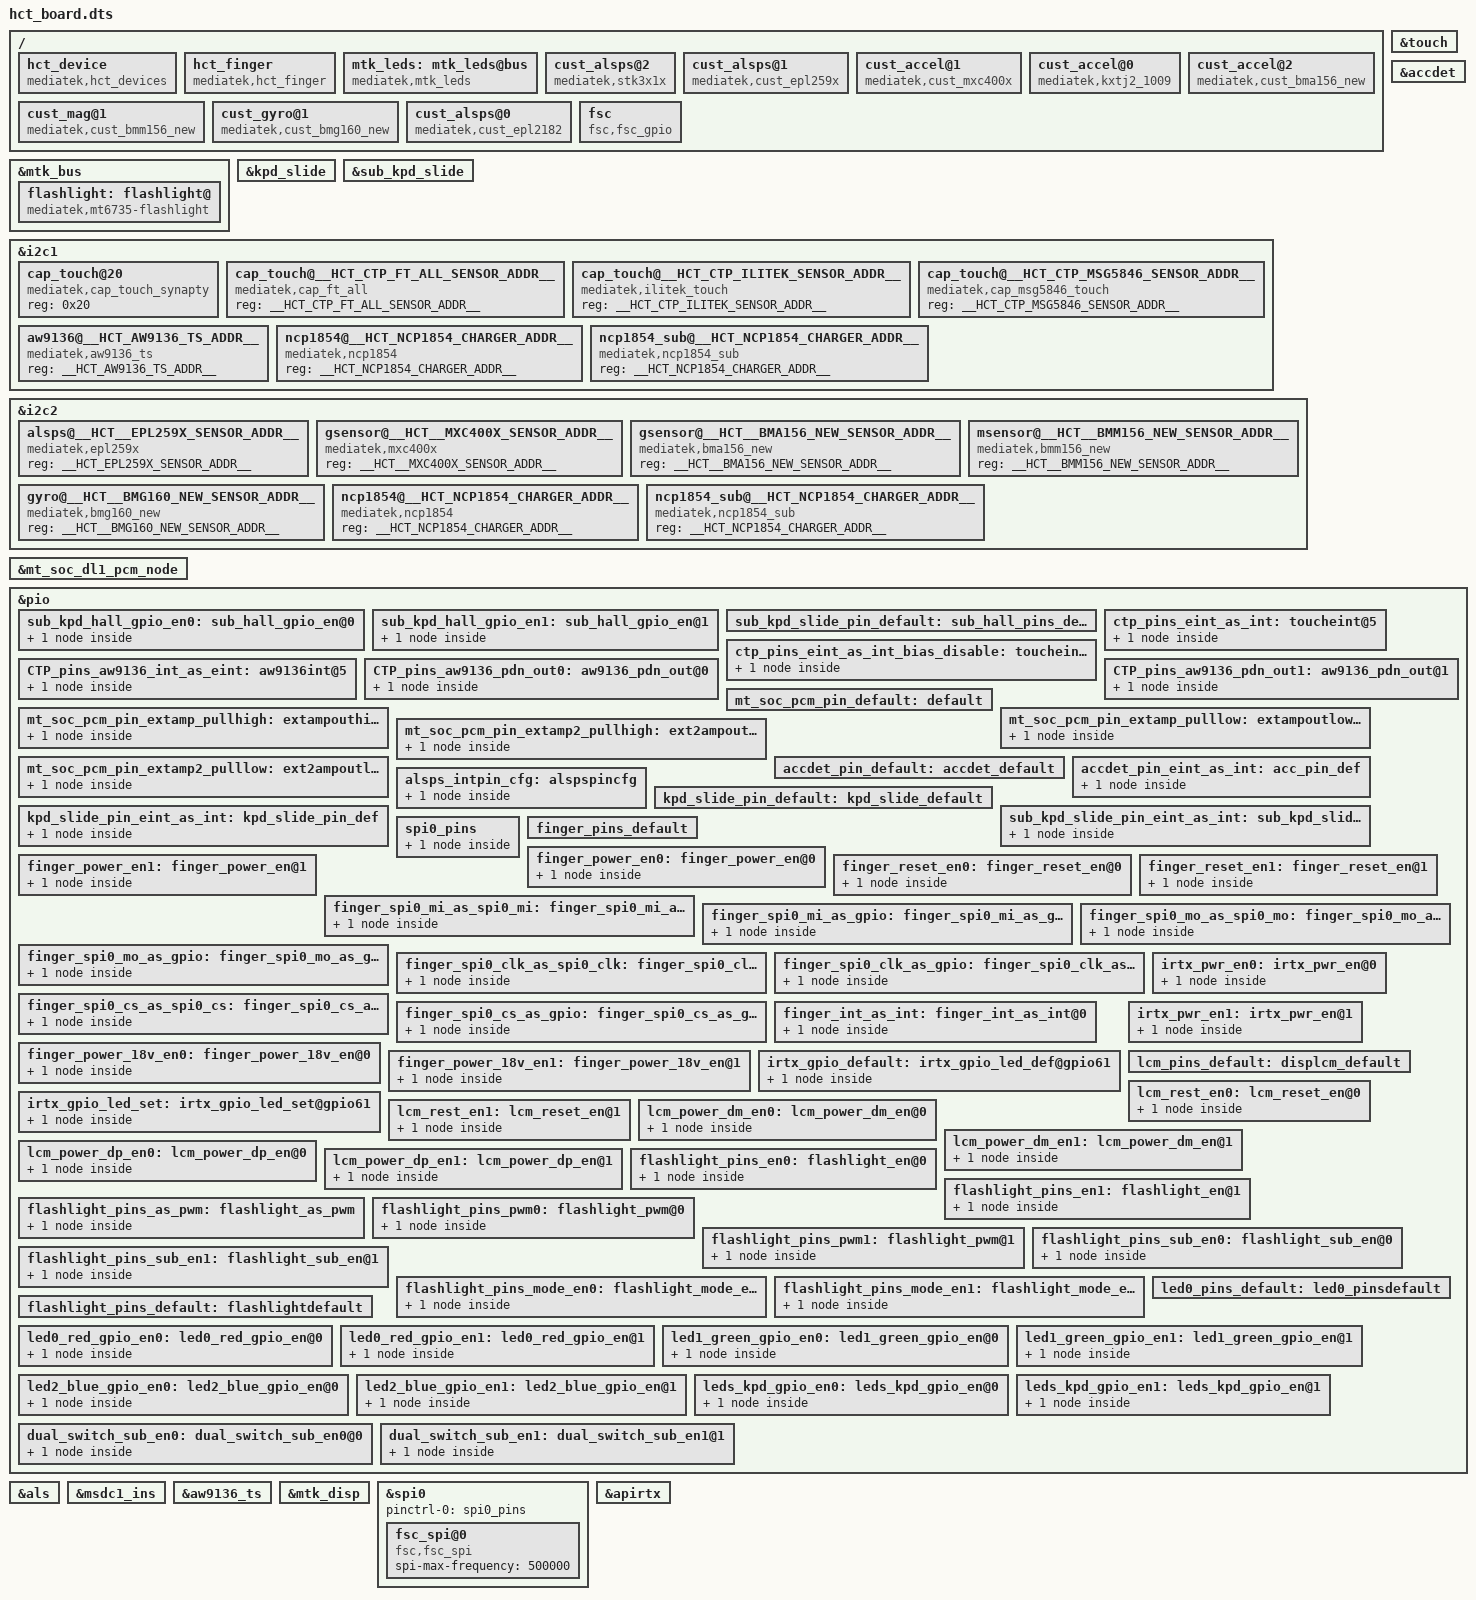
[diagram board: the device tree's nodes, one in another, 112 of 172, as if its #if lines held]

&touch {
      vtouch-supply = <&mt_pmic_vgp1_ldo_reg>;
};

&mtk_bus {



	flashlight: flashlight@ {
		compatible = "mediatek,mt6735-flashlight",
			     "mediatek,mt6735m-flashlight";
#if __HCT_FLASHLIGHT_SGM3785_SUPPORT__
		flashlight_pwmnum = <__HCT_FLASHLIGHT_PWM_NUM__>;
#endif
		status = "okay";
		};

		
};

#if __HCT_HALL_SUPPORT__
&kpd_slide {
	interrupt-parent = <&eintc>;
	interrupts = <__HCT_HALL_EINT_PIN_NUM__ IRQ_TYPE_LEVEL_LOW>;
	debounce = <__HCT_HALL_EINT_PIN_NUM__ 0>;
	hall_gpio = <&pio __HCT_HALL_EINT_GPIO_NUM__ 0>;
	status = "okay";
};

&kpd_slide {
	pinctrl-names = "default", "kpd_slide_as_int";
	pinctrl-0 = <&kpd_slide_pin_default>;
	pinctrl-1 = <&kpd_slide_pin_eint_as_int>;
	status = "okay";
};
#endif


#if __HCT_SUB_HALL_SUPPORT__
&sub_kpd_slide {
	interrupt-parent = <&eintc>;
	interrupts = <__HCT_SUB_HALL_EINT_PIN_NUM__ IRQ_TYPE_LEVEL_LOW>;
	debounce = <__HCT_SUB_HALL_EINT_PIN_NUM__ 0>;
	sub_hall_gpio = <&pio __HCT_SUB_HALL_EINT_GPIO_NUM__ 0>;
	status = "okay";
};

&sub_kpd_slide {
	pinctrl-names = "default", "sub_kpd_slide_as_int","sub_kpd_hall_gpio_en0","sub_kpd_hall_gpio_en1";
	pinctrl-0 = <&sub_kpd_slide_pin_default>;
	pinctrl-1 = <&sub_kpd_slide_pin_eint_as_int>;
	pinctrl-2 = <&sub_kpd_hall_gpio_en0>;
	pinctrl-3 = <&sub_kpd_hall_gpio_en1>;
	status = "okay";
};

#endif

&i2c1 {
	#address-cells = <1>;
	#size-cells = <0>;
	cap_touch@20 {
		compatible = "mediatek,cap_touch_synapty";
		reg = <0x20>;
		status = "okay";
	};
	cap_touch@__HCT_CTP_FT_ALL_SENSOR_ADDR__ {
		compatible = "mediatek,cap_ft_all";
		reg = <__HCT_CTP_FT_ALL_SENSOR_ADDR__>;
		status = "okay";
	};
#if defined(__HCT_CTP_ILITEK_SENSOR_ADDR__)
#if __HCT_CTP_ILITEK_SENSOR_ADDR__
	cap_touch@__HCT_CTP_ILITEK_SENSOR_ADDR__ {
		compatible = "mediatek,ilitek_touch";
		reg = <__HCT_CTP_ILITEK_SENSOR_ADDR__>;
		status = "okay";
	};
#endif
#endif

#if defined(__HCT_CTP_MSG5846_SENSOR_ADDR__)
#if __HCT_CTP_MSG5846_SENSOR_ADDR__
	cap_touch@__HCT_CTP_MSG5846_SENSOR_ADDR__ {
		compatible = "mediatek,cap_msg5846_touch";
		reg = <__HCT_CTP_MSG5846_SENSOR_ADDR__>;
		status = "okay";
	};
#endif
#endif

#if __HCT_AW9136_TS_SUPPORT__
#if __HCT_AW9136_TS_I2C_BUS_NUM__==1
        aw9136@__HCT_AW9136_TS_ADDR__{
		compatible = "mediatek,aw9136_ts";
		reg = <__HCT_AW9136_TS_ADDR__>;
		status = "okay";
	};
#endif
#endif

#if __HCT_SWITCH_CHARGER_I2C_BUS_NUM__==1
        ncp1854@__HCT_NCP1854_CHARGER_ADDR__{
		compatible = "mediatek,ncp1854",
		             "mediatek,ncp1851";
		reg = <__HCT_NCP1854_CHARGER_ADDR__>;
		status = "okay";
	};
#endif

#if __HCT_SUB_SWITCH_CHARGER_I2C_BUS_NUM__==1
        ncp1854_sub@__HCT_NCP1854_CHARGER_ADDR__{
		compatible = "mediatek,ncp1854_sub",
		             "mediatek,ncp1851_sub";
		reg = <__HCT_NCP1854_CHARGER_ADDR__>;
		status = "okay";
	};
#endif

};
&i2c2 {
	alsps@__HCT__EPL259X_SENSOR_ADDR__ {
		compatible = "mediatek,epl259x";
		reg = <__HCT_EPL259X_SENSOR_ADDR__>;
		status = "okay";
	};

	gsensor@__HCT__MXC400X_SENSOR_ADDR__ {
		compatible = "mediatek,mxc400x";
		reg = <__HCT__MXC400X_SENSOR_ADDR__>;
		status = "okay";
	};
#if __HCT_BMA156_BMM156_SUPPORT__
	gsensor@__HCT__BMA156_NEW_SENSOR_ADDR__ {
		compatible = "mediatek,bma156_new";
		reg = <__HCT__BMA156_NEW_SENSOR_ADDR__>;
		status = "okay";
	};
	msensor@__HCT__BMM156_NEW_SENSOR_ADDR__ {
		compatible = "mediatek,bmm156_new";
		reg = <__HCT__BMM156_NEW_SENSOR_ADDR__>;
		status = "okay";
	};
	gyro@__HCT__BMG160_NEW_SENSOR_ADDR__ {
		compatible = "mediatek,bmg160_new";
		reg = <__HCT__BMG160_NEW_SENSOR_ADDR__>;
		status = "okay";
	};					
#endif
#if __HCT_SWITCH_CHARGER_I2C_BUS_NUM__==2
        ncp1854@__HCT_NCP1854_CHARGER_ADDR__{
		compatible = "mediatek,ncp1854",
		             "mediatek,ncp1851";
		reg = <__HCT_NCP1854_CHARGER_ADDR__>;
		status = "okay";
	};
#endif
#if __HCT_SUB_SWITCH_CHARGER_I2C_BUS_NUM__==2
        ncp1854_sub@__HCT_NCP1854_CHARGER_ADDR__{
		compatible = "mediatek,ncp1854_sub",
		             "mediatek,ncp1851_sub";
		reg = <__HCT_NCP1854_CHARGER_ADDR__>;
		status = "okay";
	};
#endif

};

&mt_soc_dl1_pcm_node {
	pinctrl-names = "default", "extamp-pullhigh", "extamp-pulllow","extamp2-pullhigh","extamp2-pulllow";
	pinctrl-0 = <&mt_soc_pcm_pin_default>;
	pinctrl-1 = <&mt_soc_pcm_pin_extamp_pullhigh>;
	pinctrl-2 = <&mt_soc_pcm_pin_extamp_pulllow>;
	pinctrl-3 = <&mt_soc_pcm_pin_extamp2_pullhigh>;
	pinctrl-4 = <&mt_soc_pcm_pin_extamp2_pulllow>;
	status = "okay";

};

&accdet{
	pinctrl-names = "default", "state_eint_as_int";
	pinctrl-0 = <&accdet_pin_default>;
	pinctrl-1 = <&accdet_pin_eint_as_int>;
	status = "okay";
};

&pio {

#if __HCT_SUB_HALL_SUPPORT__
/*hct sub_hall en setting*/
	sub_kpd_hall_gpio_en0: sub_hall_gpio_en@0 {
	    pins_cmd_dat {
			pins = <__HCT_SUB_HALL_GPIO_EN__>;
			slew-rate = <1>;
			output-low;
		};
	};
	sub_kpd_hall_gpio_en1: sub_hall_gpio_en@1 {
	    pins_cmd_dat {
			pins = <__HCT_SUB_HALL_GPIO_EN__>;
			slew-rate = <1>;
			output-high;
		};
	};
	sub_kpd_slide_pin_default: sub_hall_pins_default {
	};
#endif
	ctp_pins_eint_as_int: toucheint@5{
			pins_cmd_dat {
				pins = <__HCT_CTP_EINT_ENT_PINNUX__>;
				slew-rate = <0>;
				bias-pull-up = <00>;
			};
	};

	ctp_pins_eint_as_int_bias_disable: toucheint_bias_dis{
			pins_cmd_dat {
				pins = <__HCT_CTP_EINT_ENT_PINNUX__>;
				slew-rate = <0>;
				bias-disable;
			};
	};

/* this pin defined is aw9136 start*/

	CTP_pins_aw9136_int_as_eint: aw9136int@5{
#if __HCT_AW9136_INT_PINNUX__
			pins_cmd_dat {
				pins = <__HCT_AW9136_INT_PINNUX__>;
				slew-rate = <0>;
				bias-pull-up = <00>;
			};
#endif
	};

	CTP_pins_aw9136_pdn_out0: aw9136_pdn_out@0 {
#if __HCT_GPIO_AW9136_PDN_PINMUX__
	    pins_cmd_dat {
			pins = <__HCT_GPIO_AW9136_PDN_PINMUX__>;
			slew-rate = <1>;
			output-low;
		};
#endif
	};

	CTP_pins_aw9136_pdn_out1: aw9136_pdn_out@1 {
#if __HCT_GPIO_AW9136_PDN_PINMUX__
	    pins_cmd_dat {
			pins = <__HCT_GPIO_AW9136_PDN_PINMUX__>;
			slew-rate = <1>;
			output-high;
		};
#endif
	};

/* this pin defined is aw9136 end*/
	mt_soc_pcm_pin_default: default {

	};

	mt_soc_pcm_pin_extamp_pullhigh: extampouthigh@0 {
	    pins_cmd_dat {
			pins = <__HCT_GPIO_EXTAMP_EN_PIN__>;
			slew-rate = <1>; /*direction 0:in, 1:out*/
			output-high;/*direction out used only. output_low or high*/
		};
	};

	mt_soc_pcm_pin_extamp_pulllow: extampoutlow@1 {
	    pins_cmd_dat {
			pins = <__HCT_GPIO_EXTAMP_EN_PIN__>;/*GPIO_CAMERA_CMRST_PIN*/
			slew-rate = <1>;
			output-low;
		};
	};

	mt_soc_pcm_pin_extamp2_pullhigh: ext2ampouthigh@3 {
#if __HCT_GPIO_EXTAMP2_EN_PIN__
	    pins_cmd_dat {
			pins = <__HCT_GPIO_EXTAMP2_EN_PIN__>;/*GPIO_CAMERA_CMRST_PIN*/
			slew-rate = <1>; /*direction 0:in, 1:out*/
			output-high;/*direction out used only. output_low or high*/
		};
#endif
	};

	mt_soc_pcm_pin_extamp2_pulllow: ext2ampoutlow@4 {
#if __HCT_GPIO_EXTAMP2_EN_PIN__
	    pins_cmd_dat {
			pins = <__HCT_GPIO_EXTAMP2_EN_PIN__>;/*GPIO_CAMERA_CMRST_PIN*/
			slew-rate = <1>;
			output-low;
		};
#endif
	};

/*Accdet*/
	accdet_pin_default:accdet_default{
	};
	accdet_pin_eint_as_int:acc_pin_def{
	    pins_cmd_dat {
			pins = <__HCT_ACCDET_EINT_PIN__>;/*HCT_ACCDET_EINT_PIN*/
			slew-rate = <0>;/*direction 0:in, 1:out*/
			bias-disable;
		};
	};
/*Alsps INT pin*/
	alsps_intpin_cfg: alspspincfg {

	    pins_cmd_dat {
			pins = <__HCT_ALSPS_EINT_PINMUX__>;
			slew-rate = <0>;
			bias-disable;
		};
	};
#if __HCT_HALL_SUPPORT__
/* Kpd_slide pin*/
	kpd_slide_pin_default:kpd_slide_default{
	};
	kpd_slide_pin_eint_as_int:kpd_slide_pin_def{
	    pins_cmd_dat {
			pins = <__HCT_KPD_SLIDE_EINT_PIN__>;/*HCT_ACCDET_EINT_PIN*/
			slew-rate = <0>;/*direction 0:in, 1:out*/
			bias-pull-up= <00> ;
		};
	};
#endif

#if __HCT_SUB_HALL_SUPPORT__
/* sub_Kpd_slide pin*/
	sub_kpd_slide_pin_eint_as_int:sub_kpd_slide_pin_def{
	    pins_cmd_dat {
			pins = <__HCT_SUB_KPD_SLIDE_EINT_PIN__>;/*HCT_SUB_ACCDET_EINT_PIN*/
			slew-rate = <0>;/*direction 0:in, 1:out*/
			bias-pull-up= <00> ;
		};
	};
#endif

};

/*EInt setting node*/
&als {
	interrupt-parent = <&eintc>;
	interrupts = <__HCT_ALSPS_EINT_PIN_NUM__ IRQ_TYPE_LEVEL_LOW>;
	debounce = <__HCT_ALSPS_EINT_PIN_NUM__ 0>;
	status = "okay";
};

&accdet {
	interrupt-parent = <&eintc>;
	interrupts = <__HCT_ACCDET_EINT_PIN_NUM__ IRQ_TYPE_LEVEL_LOW>;
	debounce = <__HCT_ACCDET_EINT_PIN_NUM__ 256000>;
	status = "okay";
};

&touch {
	interrupt-parent = <&eintc>;
	interrupts = <__HCT_CTP_EINT_EN_PIN_NUM__ IRQ_TYPE_EDGE_FALLING>;
	debounce = <__HCT_CTP_EINT_EN_PIN_NUM__ 0>;
	status = "okay";
};

#if __HCT_SD_CARD_HOTPLUG_SUPPORT__
&msdc1_ins {
	interrupt-parent = <&eintc>;
	interrupts = <__HCT_MSDC_CD_EINT_NUM__ IRQ_TYPE_LEVEL_LOW>;
	debounce = <__HCT_MSDC_CD_EINT_NUM__ 512000>;
	status = "okay";
};
#endif

#if __HCT_AW9136_TS_SUPPORT__
&aw9136_ts {
	interrupt-parent = <&eintc>;
	interrupts = <__HCT_CTP_AW9136_INT_NUM__ IRQ_TYPE_LEVEL_LOW>;
	debounce = <__HCT_CTP_AW9136_INT_NUM__ 0>;
	status = "okay";
};
#endif


/ {

hct_device: hct_device{
	compatible				= "mediatek,hct_devices";
};
#if __HCT_FINGERPRINT_SUPPORT__
hct_finger: hct_finger{
	compatible				= "mediatek,hct_finger";
};
#endif

mtk_leds: mtk_leds@bus{
	compatible				= "mediatek,mtk_leds";
};
		cust_alsps@2 {
		compatible = "mediatek,stk3x1x";
		i2c_num	= <__HCT_ALSPS_I2C_BUS_NUM__>;
		i2c_addr = <__HCT_STK3X1X_SENSOR_ADDR__ 0 0 0>;
		polling_mode_ps = <0>;
		polling_mode_als = <1>;
		power_id = <0xffff>;
		power_vol = <0>;
		als_level = <5 9 36 59 82 132 205 273 500 845 1136 1545 2364 4655 6982>;
		als_value = <10 10 80 85 90 145 225 300 550 930 1250 1700 2600 5120 7680 10240>;
		ps_threshold_high		=  <__HCT_HCT_STK3X1X_PS_THRELD_HIGH__>;
		ps_threshold_low		=  <__HCT_HCT_STK3X1X_PS_THRELD_LOW__>;
		is_batch_supported_ps	= <0>;
		is_batch_supported_als	= <0>;
		};

		cust_alsps@1 {
		compatible				= "mediatek,cust_epl259x";
		i2c_num				= <__HCT_ALSPS_I2C_BUS_NUM__>;
		i2c_addr				= <__HCT_EPL259X_SENSOR_ADDR__ 0 0 0>;
		polling_mode_ps			= <0>;
		polling_mode_als		= <1>;
		power_id				= <0xffff>;
		power_vol				= <0>;
		als_level = <0 328 861 1377 3125 7721 7767 12621 23062 28430 33274 47116 57694 57694 65535>;
		als_value = <0 133 304 502 1004 2005 3058 5005 8008 10010 12000 16000 20000 20000 20000 20000>;
		ps_threshold_high		=  <__HCT_EPL259X_PS_THRELD_HIGH__>;
		ps_threshold_low		=  <__HCT_EPL259X_PS_THRELD_LOW__>;
		is_batch_supported_ps	= <0>;
		is_batch_supported_als	= <0>;
		};

		cust_accel@1 {
		compatible				= "mediatek,cust_mxc400x";
		i2c_num				= <__HCT_GSENSOR_I2C_BUS_NUM__>;
		i2c_addr				= <__HCT__MXC400X_SENSOR_ADDR__ 0 0 0>;
		direction				= <__HCT__MXC400X_SENSOR_DIRECTION__>;
		power_id				= <0xffff>;
		power_vol				= <0>;
		firlen					= <0>;
		is_batch_supported			= <__HCT__MXC400X_SENSOR_BATCH_SUPPORT__>;
		};

		cust_accel@0 {
		compatible				= "mediatek,kxtj2_1009";
		i2c_num				        = <__HCT_GSENSOR_I2C_BUS_NUM__>;
		i2c_addr				= <__HCT__KXTJ2_SENSOR_ADDR__ 0 0 0>;
		direction				= <__HCT__KXTJ2_SENSOR_DIRECTION__>;
		power_id				= <0xffff>;
		power_vol				= <0>;
		firlen					= <0>;
		is_batch_supported			= <__HCT__KXTJ2_SENSOR_BATCH_SUPPORT__>;
		};

#if __HCT_BMA156_BMM156_SUPPORT__		
		cust_accel@2 {
		compatible				= "mediatek,cust_bma156_new";
		i2c_num				    = <__HCT_GSENSOR_I2C_BUS_NUM__>;
		i2c_addr				= <__HCT__BMA156_NEW_SENSOR_ADDR__ 0 0 0>;
		direction				= <__HCT__BMA156_NEW_SENSOR_DIRECTION__>;
		power_id				= <0xffff>;
		power_vol				= <0>;
		firlen					= <0>;
		is_batch_supported		= <__HCT__BMA156_NEW_SENSOR_BATCH_SUPPORT__>;
		};
		
		cust_mag@1 {
		compatible				= "mediatek,cust_bmm156_new";
		i2c_num					= <__HCT_MSENSOR_I2C_BUS_NUM__>;
		i2c_addr				= <__HCT__BMM156_NEW_SENSOR_ADDR__ 0 0 0>;
		direction				= <__HCT__BMM156_NEW_SENSOR_DIRECTION__>;
		power_id				= <0xffff>;
		power_vol				= <0>;
		is_batch_supported		= <__HCT__BMM156_NEW_SENSOR_BATCH_SUPPORT__>;
		};

		cust_gyro@1 {
		compatible                      = "mediatek,cust_bmg160_new";
		i2c_num                         = <__HCT_GYRO_I2C_BUS_NUM__>;
		/* i2c_addr                     = <__HCT__BMG160_NEW_SENSOR_ADDR__ 0 0 0>; */
		direction                       = <__HCT__BMG160_NEW_SENSOR_DIRECTION__>;
		power_id                        = <0xffff>;
		power_vol                       = <0>;
		firlen                          = <0>;
		is_batch_supported              = <0>;
		};

#endif
		cust_alsps@0 {
		compatible				= "mediatek,cust_epl2182";
		i2c_num				= <__HCT_ALSPS_I2C_BUS_NUM__>;
		i2c_addr				= <__HCT_EPL2182_SENSOR_ADDR__ 0 0 0>;
		polling_mode_ps			= <0>;
		polling_mode_als		= <1>;
		power_id				= <0xffff>;
		power_vol				= <0>;
		als_level = <0 328 861 1377 3125 7721 7767 12621 23062 28430 33274 47116 57694 57694 65535>;
		als_value = <0 133 304 502 1004 2005 3058 5005 8008 10010 12000 16000 20000 20000 20000 20000>;
		ps_threshold_high		=  <__HCT_EPL2182_PS_THRELD_HIGH__>;
		ps_threshold_low		=  <__HCT_EPL2182_PS_THRELD_LOW__>;
		is_batch_supported_ps	= <0>;
		is_batch_supported_als	= <0>;
		};

};

&mtk_leds {
	pinctrl-names = "default", "led0_red_gpio_en0", "led0_red_gpio_en1","led1_green_gpio_en0", "led1_green_gpio_en1" ,"led2_blue_gpio_en0", 
                          "led2_blue_gpio_en1","leds_kpd_gpio_en0","leds_kpd_gpio_en1";
	pinctrl-0 = <&led0_pins_default>;
	pinctrl-1 = <&led0_red_gpio_en0>;
	pinctrl-2 = <&led0_red_gpio_en1>;
	pinctrl-3 = <&led1_green_gpio_en0>;
	pinctrl-4 = <&led1_green_gpio_en1>;
	pinctrl-5 = <&led2_blue_gpio_en0>;
	pinctrl-6 = <&led2_blue_gpio_en1>;
	pinctrl-7 = <&leds_kpd_gpio_en0>;
	pinctrl-8 = <&leds_kpd_gpio_en1>;
};


&mtk_disp {
	pinctrl-names = "default", "lcm_rest_en0", "lcm_rest_en1","lcm_power_dm_en0","lcm_power_dm_en1","lcm_power_dp_en0","lcm_power_dp_en1";
	pinctrl-0 = <&lcm_pins_default>;
	pinctrl-1 = <&lcm_rest_en0>;
	pinctrl-2 = <&lcm_rest_en1>;
	pinctrl-3 = <&lcm_power_dm_en0>;
	pinctrl-4 = <&lcm_power_dm_en1>;
	pinctrl-5 = <&lcm_power_dp_en0>;
	pinctrl-6 = <&lcm_power_dp_en1>;
};

#if __HCT_FINGERPRINT_SUPPORT__
&hct_finger{
	pinctrl-names = "default", "finger_power_en0","finger_power_en1","finger_reset_en0","finger_reset_en1","finger_spi0_mi_as_spi0_mi","finger_spi0_mi_as_gpio",
                          "finger_spi0_mo_as_spi0_mo","finger_spi0_mo_as_gpio","finger_spi0_clk_as_spi0_clk","finger_spi0_clk_as_gpio","finger_spi0_cs_as_spi0_cs",
                          "finger_spi0_cs_as_gpio","finger_int_as_int","finger_power_18v_en0","finger_power_18v_en1";
	pinctrl-0 = <&finger_pins_default>;
	pinctrl-1 = <&finger_power_en0>;
	pinctrl-2 = <&finger_power_en1>;
	pinctrl-3 = <&finger_reset_en0>;
	pinctrl-4 = <&finger_reset_en1>;
	pinctrl-5 = <&finger_spi0_mi_as_spi0_mi>;
	pinctrl-6 = <&finger_spi0_mi_as_gpio>;
	pinctrl-7 = <&finger_spi0_mo_as_spi0_mo>;
	pinctrl-8 = <&finger_spi0_mo_as_gpio>;
	pinctrl-9 = <&finger_spi0_clk_as_spi0_clk>;
	pinctrl-10= <&finger_spi0_clk_as_gpio>;
	pinctrl-11= <&finger_spi0_cs_as_spi0_cs>;
	pinctrl-12= <&finger_spi0_cs_as_gpio>;
	pinctrl-13= <&finger_int_as_int>;
	pinctrl-14= <&finger_power_18v_en0>;
	pinctrl-15= <&finger_power_18v_en1>;
};

&hct_finger {
	interrupt-parent = <&eintc>;
	interrupts = <__HCT_FINGERPRINT_EINT_EN_PIN_NUM__ IRQ_TYPE_EDGE_FALLING>;
	debounce = <__HCT_FINGERPRINT_EINT_EN_PIN_NUM__ 0>;
	status = "okay";
};
#endif

/ {
	fsc {
		compatible = "fsc,fsc_gpio";
		/*gpio_irq  = <&pio __HCT_FINGERPRINT_EINT_EN_PIN_NUM__ 0>;
		gpio_rst  = <&pio 87 0>;*/
	};
};

&pio {
   spi0_pins: spi0_pins {                                                                                                                          
       pins_cmd_dat {
           pinmux = <PINMUX_GPIO67__FUNC_SPI_MIA>,
                    <PINMUX_GPIO65__FUNC_SPI_CSA>,
                    <PINMUX_GPIO68__FUNC_SPI_MOA>,
                    <PINMUX_GPIO66__FUNC_SPI_CKA>;
       };
   };
};

&spi0 {
	/*
	pinctrl-names = "default", "finger_spi0_mi_as_spi0_mi", "finger_spi0_mo_as_spi0_mo","finger_spi0_clk_as_spi0_clk","finger_spi0_cs_as_spi0_cs";
	pinctrl-0 = <&finger_pins_default>;
	pinctrl-1 = <&finger_spi0_mi_as_spi0_mi>;
	pinctrl-2 = <&finger_spi0_mo_as_spi0_mo>;
	pinctrl-3 = <&finger_spi0_clk_as_spi0_clk>;
	pinctrl-4 = <&finger_spi0_cs_as_spi0_cs>;
	*/
	pinctrl-names = "default";
	pinctrl-0 = <&spi0_pins>;
	status = "okay";

	fsc_spi@0 {
		compatible = "fsc,fsc_spi";
		spi-max-frequency = <500000>;
	};
};


&apirtx{
	pinctrl-names = "irtx_gpio_default", "irtx_gpio_led_set","irtx_pwr_en0","irtx_pwr_en1";
	pinctrl-0 = <&irtx_gpio_default>;
	pinctrl-1 = <&irtx_gpio_led_set>;
	pinctrl-2 = <&irtx_pwr_en0>;
	pinctrl-3 = <&irtx_pwr_en1>;
};

/* flashlight GPIO standardization */
&pio {
/*******************finger pin start ****************/
#if __HCT_FINGERPRINT_SUPPORT__
	finger_pins_default:finger_pins_default{
	};
	finger_power_en0:finger_power_en@0{
		    pins_cmd_dat {
			pins = <__HCT_FINGERPRINT_POWER_PIN__>;
			slew-rate = <1>;
			output-low;
		};
	};
	finger_power_en1:finger_power_en@1{
		    pins_cmd_dat {
			pins = <__HCT_FINGERPRINT_POWER_PIN__>;
			slew-rate = <1>;
			output-high;
		};
	};
	finger_reset_en0:finger_reset_en@0{
		    pins_cmd_dat {
			pins = <__HCT_FINGERPRINT_RESET_PIN__>;
			slew-rate = <1>;
			output-low;
		};
	};
	finger_reset_en1:finger_reset_en@1{
		    pins_cmd_dat {
			pins = <__HCT_FINGERPRINT_RESET_PIN__>;
			slew-rate = <1>;
			output-high;
		};
	};
	finger_spi0_mi_as_spi0_mi:finger_spi0_mi_as_spi0_mi@0{
		    pins_cmd_dat {
			pins = <PINMUX_GPIO67__FUNC_SPI_MIA>;
			slew-rate = <0>;
			bias-disable;
			output-low;
			input-schmitt-enable = <0>;
		};
	};
	finger_spi0_mi_as_gpio:finger_spi0_mi_as_gpio@0{
		    pins_cmd_dat {
			pins = <PINMUX_GPIO67__FUNC_GPIO67>;
			slew-rate = <0>;
			output-low;
			input-schmitt-enable = <0>;
		};
	};
	finger_spi0_mo_as_spi0_mo:finger_spi0_mo_as_spi0_mo@0{
		    pins_cmd_dat {
			pins = <PINMUX_GPIO68__FUNC_SPI_MOA>;
			slew-rate = <1>;
			bias-disable;
			output-low;
			input-schmitt-enable = <0>;
		};
	};
	finger_spi0_mo_as_gpio:finger_spi0_mo_as_gpio@0{
		    pins_cmd_dat {
			pins = <PINMUX_GPIO68__FUNC_GPIO68>;
			slew-rate = <1>;
			output-low;
			input-schmitt-enable = <0>;
		};
	};
	finger_spi0_clk_as_spi0_clk:finger_spi0_clk_as_spi0_clk@0{
		    pins_cmd_dat {
			pins = <PINMUX_GPIO66__FUNC_SPI_CKA>;
			slew-rate = <1>;
			bias-disable;
			output-low;
			input-schmitt-enable = <0>;
		};
	};
	finger_spi0_clk_as_gpio:finger_spi0_clk_as_gpio@0{
		    pins_cmd_dat {
			pins = <PINMUX_GPIO66__FUNC_GPIO66>;
			slew-rate = <1>;
			output-low;
			input-schmitt-enable = <0>;
		};
	};
	finger_spi0_cs_as_spi0_cs:finger_spi0_cs_as_spi0_cs@0{
		    pins_cmd_dat {
			pins = <PINMUX_GPIO65__FUNC_SPI_CSA>;
			slew-rate = <1>;
			bias-disable;
			output-low;
			input-schmitt-enable = <0>;
		};
	};
	finger_spi0_cs_as_gpio:finger_spi0_cs_as_gpio@0{
		    pins_cmd_dat {
			pins = <PINMUX_GPIO65__FUNC_GPIO65>;
			slew-rate = <1>;
			output-low;
			input-schmitt-enable = <0>;
		};
	};
	finger_int_as_int: finger_int_as_int@0{
			pins_cmd_dat {
				pins = <__HCT_FINGERPRINT_EINT_PIN__>;
				slew-rate = <0>;
				bias-pull-up = <00>;
			};
	};
	finger_power_18v_en0:finger_power_18v_en@0{
#if __HCT_FINGERPRINT_POWER_18V_PIN__	
		    pins_cmd_dat {
	    
			pins = <__HCT_FINGERPRINT_POWER_18V_PIN__>;
			slew-rate = <1>;
			output-low;		
		};
#endif	
	};
	finger_power_18v_en1:finger_power_18v_en@1{
#if __HCT_FINGERPRINT_POWER_18V_PIN__
		    pins_cmd_dat {	    		    
			pins = <__HCT_FINGERPRINT_POWER_18V_PIN__>;
			slew-rate = <1>;
			output-high;
		
		};
#endif	
	};
#endif
/*******************finger pin end ****************/

/* IRTX GPIO Settings -Start */
         /* default: GPIO0, output, high */
         irtx_gpio_default:irtx_gpio_led_def@gpio61 {
#if __HCT_IRTX_OUT_PIN_DEFAULT__
             pins_cmd_dat {
                         pins = <__HCT_IRTX_OUT_PIN_DEFAULT__>;
                         slew-rate = <1>;
                         bias-disable;
                         output-high;
                         input-schmitt-enable = <0>;
                 };
#endif
         };
 
         irtx_gpio_led_set:irtx_gpio_led_set@gpio61 {
#if __HCT_IRTX_OUT_PIN_LED_EN__
             pins_cmd_dat {
                        pins = <__HCT_IRTX_OUT_PIN_LED_EN__>;
                 };
#endif
         };
	irtx_pwr_en0:irtx_pwr_en@0{
#if __HCT_IRTX_PWR_EN_PIN__
		    pins_cmd_dat {
			pins = <__HCT_IRTX_PWR_EN_PIN__>;
			slew-rate = <1>;
			output-low;
		};
#endif
	};
	irtx_pwr_en1:irtx_pwr_en@1{
#if __HCT_IRTX_PWR_EN_PIN__
		    pins_cmd_dat {
			pins = <__HCT_IRTX_PWR_EN_PIN__>;
			slew-rate = <1>;
			output-high;
		};
#endif
	};
         /* IRTX GPIO Settings -End */



/*******************irtx pin end ****************/	
/*******************lcm pin start *****************/
	lcm_pins_default: displcm_default {
	};

	lcm_rest_en0: lcm_reset_en@0 {
	    pins_cmd_dat {
			pins = <PINMUX_GPIO146__FUNC_GPIO146>;
			slew-rate = <1>;
			output-low;
		};
	};
	lcm_rest_en1: lcm_reset_en@1 {
	    pins_cmd_dat {
			pins = <PINMUX_GPIO146__FUNC_GPIO146>;
			slew-rate = <1>;
			output-high;
		};
	};

	lcm_power_dm_en0: lcm_power_dm_en@0 {
#if __HCT_GPIO_LCM_POWER_DM_PINMUX__
	    pins_cmd_dat {
			pins = <__HCT_GPIO_LCM_POWER_DM_PINMUX__>;
			slew-rate = <1>;
			output-low;
		};
#endif
	};
	lcm_power_dm_en1: lcm_power_dm_en@1 {
#if __HCT_GPIO_LCM_POWER_DM_PINMUX__
	    pins_cmd_dat {
			pins = <__HCT_GPIO_LCM_POWER_DM_PINMUX__>;
			slew-rate = <1>;
			output-high;
		};
#endif
	};

	lcm_power_dp_en0: lcm_power_dp_en@0 {
#if __HCT_GPIO_LCM_POWER_DP_PINMUX__
	    pins_cmd_dat {
			pins = <__HCT_GPIO_LCM_POWER_DP_PINMUX__>;
			slew-rate = <1>;
			output-low;
		};
#endif
	};

	lcm_power_dp_en1: lcm_power_dp_en@1 {
#if __HCT_GPIO_LCM_POWER_DP_PINMUX__
	    pins_cmd_dat {
			pins = <__HCT_GPIO_LCM_POWER_DP_PINMUX__>;
			slew-rate = <1>;
			output-high;
		};
#endif
	};

/*******************lcm pin end********************/




	flashlight_pins_en0: flashlight_en@0 {
	    pins_cmd_dat {
			pins = <__HCT_GPIO_FLASHLIGHT_EN_PIN__>;
			slew-rate = <1>;
			output-low;
		};
	};
	flashlight_pins_en1: flashlight_en@1 {
	    pins_cmd_dat {
			pins = <__HCT_GPIO_FLASHLIGHT_EN_PIN__>;
			slew-rate = <1>;
			output-high;
		};
	};
	flashlight_pins_as_pwm: flashlight_as_pwm {
#if __HCT_FLASHLIGHT_SGM3785_SUPPORT__
	    pins_cmd_dat {
			pins = <__HCT_GPIO_FLASHLIGHT_PWM_AS_PWM_PIN__>;
			slew-rate = <1>;
		};
#endif
	};
	flashlight_pins_pwm0: flashlight_pwm@0 {
#if __HCT_FLASHLIGHT_SGM3785_SUPPORT__
	    pins_cmd_dat {
			pins = <__HCT_GPIO_FLASHLIGHT_PWM_AS_GPIO_PIN__>;
			slew-rate = <1>;
			output-low;
		};
#endif
	};
	flashlight_pins_pwm1: flashlight_pwm@1 {
#if __HCT_FLASHLIGHT_SGM3785_SUPPORT__
	    pins_cmd_dat {
			pins = <__HCT_GPIO_FLASHLIGHT_PWM_AS_GPIO_PIN__>;
			slew-rate = <1>;
			output-high;
		};
#endif
	};
	flashlight_pins_sub_en0: flashlight_sub_en@0 {
#if __HCT_SUB_FLASHLIGHT_SUPPORT__
	    pins_cmd_dat {
			pins = <__HCT_GPIO_FLASHLIGHT_SUB_EN_PIN__>;
			slew-rate = <1>;
			output-low;
		};
#endif
	};
	flashlight_pins_sub_en1: flashlight_sub_en@1 {
#if __HCT_SUB_FLASHLIGHT_SUPPORT__
	    pins_cmd_dat {
			pins = <__HCT_GPIO_FLASHLIGHT_SUB_EN_PIN__>;
			slew-rate = <1>;
			output-high;
		};
#endif
	};


	flashlight_pins_mode_en0: flashlight_mode_en@0 {
#if __HCT_FLASHLIGHT_AW3641_SUPPORT__||__HCT_FLASHLIGHT_AW3141_SUPPORT__
	    pins_cmd_dat {
			pins = <__HCT_GPIO_FLASHLIGHT_MODE_PINMUX__>;
			slew-rate = <1>;
			output-low;
		};
#endif
	};
	flashlight_pins_mode_en1: flashlight_mode_en@1 {
#if __HCT_FLASHLIGHT_AW3641_SUPPORT__||__HCT_FLASHLIGHT_AW3141_SUPPORT__
	    pins_cmd_dat {
			pins = <__HCT_GPIO_FLASHLIGHT_MODE_PINMUX__>;
			slew-rate = <1>;
			output-high;
		};
#endif
	};

	flashlight_pins_default: flashlightdefault {
	};


	led0_pins_default: led0_pinsdefault {
	};

/*hct red gpio setting*/

	led0_red_gpio_en0: led0_red_gpio_en@0 {
#if __HCT_RED_LED_MODE__ == __HCT_MT65XX_LED_MODE_GPIO_R__
	    pins_cmd_dat {
			pins = <__HCT_GPIO_RED_GPIO_EN_PIN__>;
			slew-rate = <1>;
			output-low;
		};
#endif
	};
	led0_red_gpio_en1: led0_red_gpio_en@1 {
#if __HCT_RED_LED_MODE__ ==__HCT_MT65XX_LED_MODE_GPIO_R__
	    pins_cmd_dat {
			pins = <__HCT_GPIO_RED_GPIO_EN_PIN__>;
			slew-rate = <1>;
			output-high;
		};
#endif
	};


/*hct green gpio setting*/

	led1_green_gpio_en0: led1_green_gpio_en@0 {
#if __HCT_GREEN_LED_MODE__ ==__HCT_MT65XX_LED_MODE_GPIO_G__
	    pins_cmd_dat {
			pins = <__HCT_GPIO_GREEN_GPIO_EN_PIN__>;
			slew-rate = <1>;
			output-low;
		};
#endif
	};
	led1_green_gpio_en1: led1_green_gpio_en@1 {
#if __HCT_GREEN_LED_MODE__ ==__HCT_MT65XX_LED_MODE_GPIO_G__
	    pins_cmd_dat {
			pins = <__HCT_GPIO_GREEN_GPIO_EN_PIN__>;
			slew-rate = <1>;
			output-high;
		};
#endif
	};


/*hct blue gpio setting*/

	led2_blue_gpio_en0: led2_blue_gpio_en@0 {
#if __HCT_BLUE_LED_MODE__ ==__HCT_MT65XX_LED_MODE_GPIO_B__
	    pins_cmd_dat {
			pins = <__HCT_GPIO_BLUE_GPIO_EN_PIN__>;
			slew-rate = <1>;
			output-low;
		};
#endif
	};

	led2_blue_gpio_en1: led2_blue_gpio_en@1 {
#if __HCT_BLUE_LED_MODE__ ==__HCT_MT65XX_LED_MODE_GPIO_B__
	    pins_cmd_dat {
			pins = <__HCT_GPIO_BLUE_GPIO_EN_PIN__>;
			slew-rate = <1>;
			output-high;
		};
#endif
	};




	leds_kpd_gpio_en0: leds_kpd_gpio_en@0 {
#if __HCT_BUTTON_BACKLIGHT_LED_MODE__ == __HCT_MT65XX_LED_MODE_GPIO_KPD__
	    pins_cmd_dat {
			pins = <__HCT_GPIO_BUTTON_BACKLIGHT_GPIO_EN_PIN__>;
			slew-rate = <1>;
			output-low;
		};
#endif
	};
	leds_kpd_gpio_en1: leds_kpd_gpio_en@1 {
#if __HCT_BUTTON_BACKLIGHT_LED_MODE__ == __HCT_MT65XX_LED_MODE_GPIO_KPD__
	    pins_cmd_dat {
			pins = <__HCT_GPIO_BUTTON_BACKLIGHT_GPIO_EN_PIN__>;
			slew-rate = <1>;
			output-high;
		};
#endif
	};

        dual_switch_sub_en0: dual_switch_sub_en0@0 {
#if __HCT_DUAL_SWITCH_SUB_EN_PINMUX__
	    pins_cmd_dat {
			pins = <__HCT_DUAL_SWITCH_SUB_EN_PINMUX__>;
			slew-rate = <1>;
			output-low;
		};
#endif
        };

        dual_switch_sub_en1: dual_switch_sub_en1@1 {
#if __HCT_DUAL_SWITCH_SUB_EN_PINMUX__
	    pins_cmd_dat {
			pins = <__HCT_DUAL_SWITCH_SUB_EN_PINMUX__>;
			slew-rate = <1>;
			output-high;
		};
#endif
        };

};

&flashlight {
	pinctrl-names = "default", "flashlight_en0", "flashlight_en1", "flashlight_as_pwm", "flashlight_pwm0", "flashlight_pwm1",
			"flashlight_sub_en0", "flashlight_sub_en1", "flashlight_mode0", "flashlight_mode1", "dual_switch_sub_en0", "dual_switch_sub_en1";
	pinctrl-0 = <&flashlight_pins_default>;
	pinctrl-1 = <&flashlight_pins_en0>;
	pinctrl-2 = <&flashlight_pins_en1>;
	pinctrl-3 = <&flashlight_pins_as_pwm>;
	pinctrl-4 = <&flashlight_pins_pwm0>;
	pinctrl-5 = <&flashlight_pins_pwm1>;
	pinctrl-6 = <&flashlight_pins_sub_en0>;
	pinctrl-7 = <&flashlight_pins_sub_en1>;
	pinctrl-8 = <&flashlight_pins_mode_en0>;
	pinctrl-9 = <&flashlight_pins_mode_en1>;
	pinctrl-10 = <&dual_switch_sub_en0>;
	pinctrl-11 = <&dual_switch_sub_en1>;
	status = "okay";

};
/* flashlight GPIO end */
